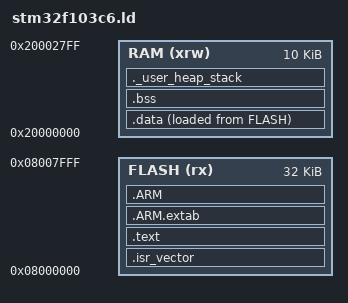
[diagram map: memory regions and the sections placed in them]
/* STM32F103C6: 32 KiB flash, 10 KiB SRAM. */
ENTRY(Reset_Handler)

MEMORY
{
  FLASH (rx)  : ORIGIN = 0x08000000, LENGTH = 32K
  RAM (xrw)   : ORIGIN = 0x20000000, LENGTH = 10K
}

_estack = ORIGIN(RAM) + LENGTH(RAM);
_Min_Heap_Size = 0;
_Min_Stack_Size = 0x400;

SECTIONS
{
  .isr_vector :
  {
    . = ALIGN(4);
    KEEP(*(.isr_vector))
    . = ALIGN(4);
  } >FLASH

  .text :
  {
    . = ALIGN(4);
    *(.text*)
    *(.rodata*)
    KEEP(*(.init))
    KEEP(*(.fini))
    . = ALIGN(4);
    _etext = .;
  } >FLASH

  .ARM.extab : { *(.ARM.extab* .gnu.linkonce.armextab.*) } >FLASH
  .ARM : { __exidx_start = .; *(.ARM.exidx* .gnu.linkonce.armexidx.*) __exidx_end = .; } >FLASH

  _sidata = LOADADDR(.data);
  .data :
  {
    . = ALIGN(4);
    _sdata = .;
    *(.data*)
    . = ALIGN(4);
    _edata = .;
  } >RAM AT> FLASH

  .bss :
  {
    . = ALIGN(4);
    _sbss = .;
    *(.bss*)
    *(COMMON)
    . = ALIGN(4);
    _ebss = .;
  } >RAM

  ._user_heap_stack :
  {
    . = ALIGN(8);
    . = . + _Min_Heap_Size;
    . = . + _Min_Stack_Size;
    . = ALIGN(8);
  } >RAM

  /DISCARD/ : { libgcc.a ( * ) libc_nano.a ( * ) libm.a ( * ) }
}
